# soc register map
Vendor: litex
Registers are 32-bit, read-write, reset 0x0 unless marked. A register's access mark holds for its fields unless they carry their own. Offsets are from the block's base; [hi:lo] are bit positions.

## TRNG_KERNEL
Base 0xF001B000
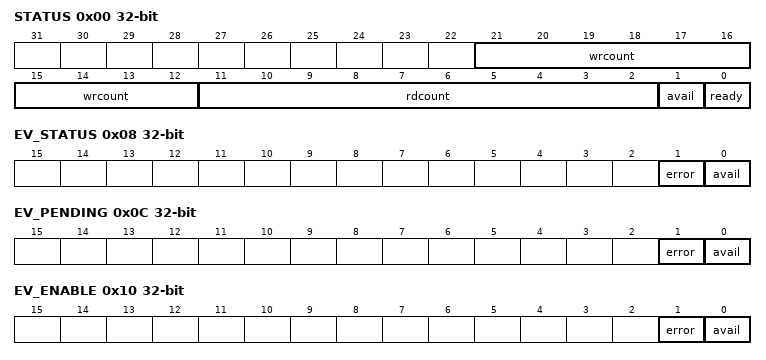
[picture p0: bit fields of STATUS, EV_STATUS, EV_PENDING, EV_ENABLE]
0x00 STATUS
  [21:12] wrcount — Write fifo pointer
  [11:2] rdcount — Read fifo pointer
  [1] avail — Indicates that the read FIFO is not empty
  [0] ready — When set, indicates that the TRNG interface is capable of generating numbers
0x04 DATA
  [31:0] data — Latest random data from the FIFO; only valid if ``avail`` bit is set
0x08 EV_STATUS — Triggered whenever an underrun condition first occurs on the kernel interface
  [1] error — Level of the ``error`` event
  [0] avail — Level of the ``avail`` event
0x0C EV_PENDING — Triggered whenever an underrun condition first occurs on the kernel interface
  [1] error — Triggered whenever an underrun condition first occurs on the kernel interface
  [0] avail — Triggered anytime there is data available on the kernel interface
0x10 EV_ENABLE — Triggered whenever an underrun condition first occurs on the kernel interface
  [1] error — Write a ``1`` to enable the ``error`` Event
  [0] avail — Write a ``1`` to enable the ``avail`` Event

## TRNG_SERVER
Base 0xF001C000
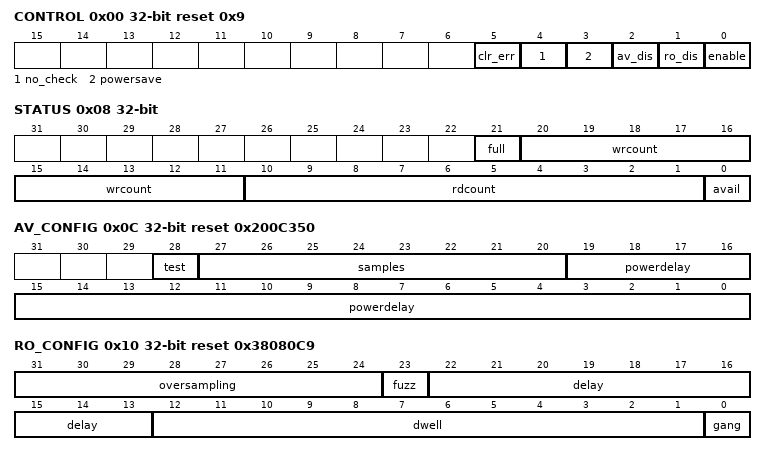
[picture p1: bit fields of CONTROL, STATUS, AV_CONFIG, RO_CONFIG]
0x00 CONTROL reset 0x9
  [5] clr_err — Write ``1`` to this bit to clear the ``errors`` register
  [4] no_check — When set, disables on-line health checking (for power saving)
  [3] powersave — When set, TRNGs are automatically turned off until the low water mark is hit; when cleared, TRNGs are always on
  [2] av_dis — When set, disables the avalanche generator as an entropy source
  [1] ro_dis — When set, disables the ring oscillator as an entropy source
  [0] enable — Power on the management interface and auto-fill random numbers
0x04 DATA
  [31:0] data — Latest random data from the FIFO; only valid if available bit is set
0x08 STATUS
  [21] full — Both kernel and server FIFOs have been topped off
  [20:11] wrcount — Write fifo pointer
  [10:1] rdcount — Read fifo pointer
  [0] avail — FIFO data is available
0x0C AV_CONFIG reset 0x200C350
  [28] test — When set, puts the generator into test mode -- full-size, raw ADC samples are directly placed into the FIFO at full rate, creating a 'virtual oscilloscope' snapshot of the avalanche generator waveform.
  [27:20] samples — Number of samples to fold into a single result. Smaller values increase rate but decrease quality. Default is 32.
  [19:0] powerdelay — Delay in microseconds for avalanche generator to stabilize
0x10 RO_CONFIG reset 0x38080C9
  [31:24] oversampling — Number of stages to oversample entropy. Normally, each bit is just sampled and shifted once (so 32 times for 32-bit word). Each increment of oversampling will add another stage.
  [23] fuzz — Modulate the `delay`/`dwell` parameter slightly from run-to-run, based on previous run's random values. May help to break ring oscillator resonances trained by the delay/dwell periodicity.
  [22:13] delay — Sampler delay time. Sets the delay between when the small rings are merged together, and when the final entropy result is sampled. Value encodes number of sysclk edges to pass during the delay period. Delay should be long enough for the signal to propagate around the merged ring, but longer times also means more coupling of the deterministic sysclk noise into the rings.
  [12:1] dwell — Prescaler to set dwell-time of entropy collection. Controls the period of how long the oscillators are in a metastable state to collect entropy before sampling. Value encodes the number of sysclk edges to pass during the dwell period.
  [0] gang — Fold in collective gang entropy during dwell time
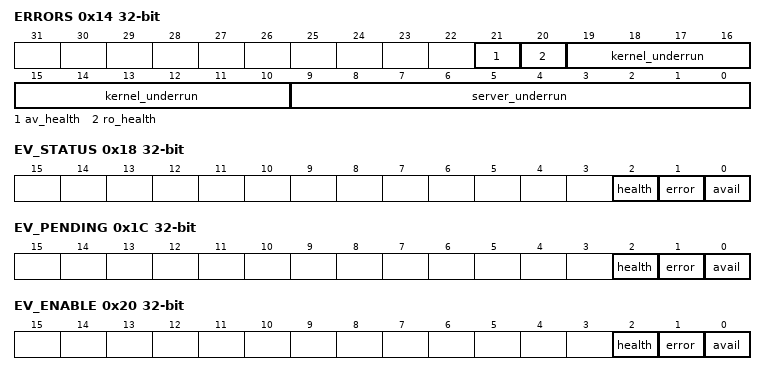
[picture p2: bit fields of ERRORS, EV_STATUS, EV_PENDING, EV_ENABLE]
0x14 ERRORS
  [21] av_health — When `1`, Avalanche generator has failed an on-line health test
  [20] ro_health — When `1`, Ring oscillator has failed an on-line health test
  [19:10] kernel_underrun — If non-zero, a kernel underrun has occurred. Will count number of underruns up to max field size
  [9:0] server_underrun — If non-zero, a server underrun has occurred. Will count number of underruns up to max field size
0x18 EV_STATUS — Triggered whenever a health event first occurs
  [2] health — Level of the ``health`` event
  [1] error — Level of the ``error`` event
  [0] avail — Level of the ``avail`` event
0x1C EV_PENDING — Triggered whenever a health event first occurs
  [2] health — Triggered whenever a health event first occurs
  [1] error — Triggered whenever an error condition first occurs on the server interface
  [0] avail — Triggered anytime there is data available on the server interface
0x20 EV_ENABLE — Triggered whenever a health event first occurs
  [2] health — Write a ``1`` to enable the ``health`` Event
  [1] error — Write a ``1`` to enable the ``error`` Event
  [0] avail — Write a ``1`` to enable the ``avail`` Event
